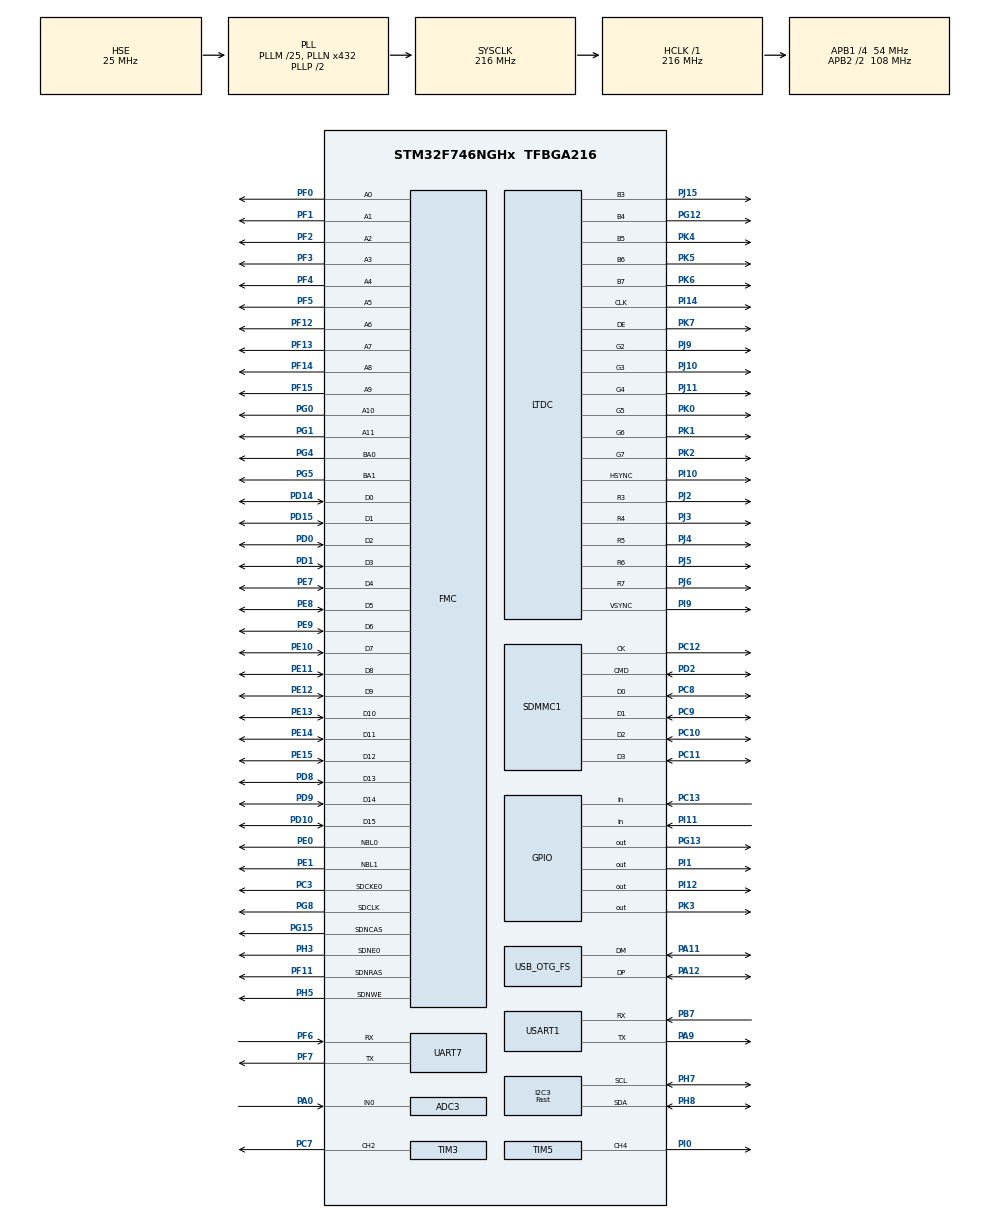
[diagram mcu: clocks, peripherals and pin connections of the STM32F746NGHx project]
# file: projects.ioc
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ADC3.Channel-0\#ChannelRegularConversion=ADC_CHANNEL_0
ADC3.ContinuousConvMode=DISABLE
ADC3.DMAContinuousRequests=ENABLE
ADC3.ExternalTrigConv=ADC_EXTERNALTRIGCONV_T2_CC2
ADC3.NbrOfConversion=1
ADC3.NbrOfConversionFlag=1
ADC3.Rank-0\#ChannelRegularConversion=1
ADC3.SamplingTime-0\#ChannelRegularConversion=ADC_SAMPLETIME_15CYCLES
ADC3.ScanConvMode=ADC_SCAN_DISABLE
CORTEX_M7.CPU_DCache=Disabled
CORTEX_M7.CPU_ICache=Enabled
CORTEX_M7.MPU_Control=__NULL
CORTEX_M7.PREFETCH_ENABLE=1
Dma.ADC3.0.Direction=DMA_PERIPH_TO_MEMORY
Dma.ADC3.0.FIFOMode=DMA_FIFOMODE_DISABLE
Dma.ADC3.0.Instance=DMA2_Stream1
Dma.ADC3.0.MemDataAlignment=DMA_MDATAALIGN_HALFWORD
Dma.ADC3.0.MemInc=DMA_MINC_ENABLE
Dma.ADC3.0.Mode=DMA_CIRCULAR
Dma.ADC3.0.PeriphDataAlignment=DMA_PDATAALIGN_HALFWORD
Dma.ADC3.0.PeriphInc=DMA_PINC_DISABLE
Dma.ADC3.0.Priority=DMA_PRIORITY_LOW
Dma.Request0=ADC3
Dma.Request1=SDMMC1_RX
Dma.Request2=SDMMC1_TX
Dma.Request3=TIM5_CH4/TRIG
Dma.SDMMC1_RX.1.Direction=DMA_PERIPH_TO_MEMORY
Dma.SDMMC1_RX.1.FIFOMode=DMA_FIFOMODE_ENABLE
Dma.SDMMC1_RX.1.FIFOThreshold=DMA_FIFO_THRESHOLD_FULL
Dma.SDMMC1_RX.1.Instance=DMA2_Stream3
Dma.SDMMC1_RX.1.MemBurst=DMA_MBURST_INC4
Dma.SDMMC1_RX.1.MemDataAlignment=DMA_MDATAALIGN_WORD
Dma.SDMMC1_RX.1.MemInc=DMA_MINC_ENABLE
Dma.SDMMC1_RX.1.Mode=DMA_PFCTRL
Dma.SDMMC1_RX.1.PeriphBurst=DMA_PBURST_INC4
Dma.SDMMC1_RX.1.PeriphDataAlignment=DMA_PDATAALIGN_WORD
Dma.SDMMC1_RX.1.PeriphInc=DMA_PINC_DISABLE
Dma.SDMMC1_RX.1.Priority=DMA_PRIORITY_LOW
Dma.SDMMC1_TX.2.Direction=DMA_MEMORY_TO_PERIPH
Dma.SDMMC1_TX.2.FIFOMode=DMA_FIFOMODE_ENABLE
Dma.SDMMC1_TX.2.FIFOThreshold=DMA_FIFO_THRESHOLD_FULL
Dma.SDMMC1_TX.2.Instance=DMA2_Stream6
Dma.SDMMC1_TX.2.MemBurst=DMA_MBURST_INC4
Dma.SDMMC1_TX.2.MemDataAlignment=DMA_MDATAALIGN_WORD
Dma.SDMMC1_TX.2.MemInc=DMA_MINC_ENABLE
Dma.SDMMC1_TX.2.Mode=DMA_PFCTRL
Dma.SDMMC1_TX.2.PeriphBurst=DMA_PBURST_INC4
Dma.SDMMC1_TX.2.PeriphDataAlignment=DMA_PDATAALIGN_WORD
Dma.SDMMC1_TX.2.PeriphInc=DMA_PINC_DISABLE
Dma.SDMMC1_TX.2.Priority=DMA_PRIORITY_LOW
Dma.TIM5_CH4/TRIG.3.Direction=DMA_MEMORY_TO_PERIPH
Dma.TIM5_CH4/TRIG.3.FIFOMode=DMA_FIFOMODE_DISABLE
Dma.TIM5_CH4/TRIG.3.Instance=DMA1_Stream1
Dma.TIM5_CH4/TRIG.3.MemDataAlignment=DMA_MDATAALIGN_WORD
Dma.TIM5_CH4/TRIG.3.MemInc=DMA_MINC_ENABLE
Dma.TIM5_CH4/TRIG.3.Mode=DMA_NORMAL
Dma.TIM5_CH4/TRIG.3.PeriphDataAlignment=DMA_PDATAALIGN_WORD
Dma.TIM5_CH4/TRIG.3.PeriphInc=DMA_PINC_DISABLE
Dma.TIM5_CH4/TRIG.3.Priority=DMA_PRIORITY_LOW
FATFS.BSP.number=1
FATFS._FS_LOCK=4
FATFS._USE_LFN=2
FATFS0.BSP.STBoard=false
FATFS0.BSP.api=Unknown
FATFS0.BSP.i2caddr=0
FATFS0.BSP.instance=PC13
FATFS0.BSP.ip=GPIO
FATFS0.BSP.mode=Input
FATFS0.BSP.name=Detect_SDIO
FATFS0.BSP.solution=PC13
FMC.CASLatency1=FMC_SDRAM_CAS_LATENCY_3
FMC.ExitSelfRefreshDelay1=7
FMC.LoadToActiveDelay1=2
FMC.RCDDelay1=2
FMC.RPDelay1=2
FMC.ReadBurst1=FMC_SDRAM_RBURST_ENABLE
FMC.RowCycleDelay1=7
FMC.SDClockPeriod1=FMC_SDRAM_CLOCK_PERIOD_2
FMC.SelfRefreshTime1=4
FMC.WriteRecoveryTime1=3
FREERTOS.Tasks01=defaultTask,0,128,StartDefaultTask,Default,NULL,Dynamic,NULL,NULL
FREERTOS.configTOTAL_HEAP_SIZE=30720
FREERTOS.configUSE_IDLE_HOOK=1
FREERTOS.configUSE_TICK_HOOK=1
FREERTOS.configUSE_TIMERS=1
GRAPHICS.BSP.number=1
GRAPHICS.Check_OTM8009A_PixelFormat-STemWin=1
GRAPHICS.DMA2D_Graphics-STemWin=0
GRAPHICS.EA_1_Apptype=Window
GRAPHICS.EA_1_custom_path=custom_off
GRAPHICS.EA_1_executable_name-STemWin=GUIBuilder.exe
GRAPHICS.GUI_NUM_LAYERS-STemWin=1
GRAPHICS.GUI_Num_KBYTES=40
GRAPHICS.LIN_Color_Conversion_Layer0=GUICC_M565
GRAPHICS.LIN_Frame_Buffer_Depth_Layer0-STemWin=16
GRAPHICS.Num_MultBuffers=1
GRAPHICS.Num_VScreens=1
GRAPHICS.OPTIM_OS_use-STemWin=2
GRAPHICS.USE_Embedded_Wizard-STemWin=0
GRAPHICS.USE_STTouchGFX-STemWin=0
GRAPHICS.UseGUIBuilder=Disabled
GRAPHICS.Use_SDRAM-STemWin=SDRAM1_BANK1
GRAPHICS0.BSP.STBoard=false
GRAPHICS0.BSP.api=Unknown
GRAPHICS0.BSP.i2caddr=0
GRAPHICS0.BSP.instance=PG13
GRAPHICS0.BSP.ip=GPIO
GRAPHICS0.BSP.mode=Output
GRAPHICS0.BSP.name=LCD Reset Pin XRES
GRAPHICS0.BSP.solution=PG13
I2C3.I2C_Speed_Mode=I2C_Fast
I2C3.Timing=0x6000030D
LTDC.ActiveH=272
LTDC.ActiveW=480
LTDC.Alpha_L0=255
LTDC.Blue_L0=0
LTDC.Blue_L1=22
LTDC.FBStartAdress_L0=0xC0000000
LTDC.FBStartAdress_L1=0x20050000
LTDC.Green_L0=0
LTDC.Green_L1=33
LTDC.HBP=43
LTDC.HFP=8
LTDC.HSync=1
LTDC.ImageHeight_L0=272
LTDC.ImageHeight_L1=272
LTDC.ImageWidth_L0=480
LTDC.ImageWidth_L1=480
LTDC.Layers=0
LTDC.PixelFormat_L0=LTDC_PIXEL_FORMAT_RGB565
LTDC.PixelFormat_L1=LTDC_PIXEL_FORMAT_RGB565
LTDC.Red_L0=0
LTDC.Red_L1=44
LTDC.VBP=12
LTDC.VFP=4
LTDC.VSync=10
LTDC.WindowX1_L0=480
LTDC.WindowX1_L1=480
LTDC.WindowY1_L0=272
LTDC.WindowY1_L1=272
Mcu.Family=STM32F7
Mcu.Name=STM32F746NGHx
Mcu.Package=TFBGA216
NVIC.ADC_IRQn=true\:5\:0\:false\:false\:true\:true\:true\:true
NVIC.DMA1_Stream1_IRQn=true\:5\:0\:true\:false\:true\:false\:false\:true
NVIC.DMA2_Stream1_IRQn=true\:5\:0\:true\:false\:true\:true\:false\:true
NVIC.DMA2_Stream3_IRQn=true\:5\:0\:false\:false\:true\:true\:false\:true
NVIC.DMA2_Stream6_IRQn=true\:5\:0\:true\:false\:true\:true\:false\:true
NVIC.OTG_FS_IRQn=true\:5\:0\:false\:false\:true\:true\:false\:true
NVIC.PriorityGroup=NVIC_PRIORITYGROUP_4
NVIC.SDMMC1_IRQn=true\:10\:0\:true\:false\:true\:true\:true\:true
NVIC.TIM1_UP_TIM10_IRQn=true\:0\:0\:false\:false\:true\:false\:false\:true
NVIC.TIM8_BRK_TIM12_IRQn=true\:1\:0\:true\:false\:true\:false\:true\:true
NVIC.TimeBase=TIM1_UP_TIM10_IRQn
NVIC.TimeBaseIP=TIM1
NVIC.USART1_IRQn=true\:5\:0\:false\:false\:true\:true\:true\:true
PA0/WKUP.Signal=ADCx_IN0
PA11.Mode=Device_Only
PA11.Signal=USB_OTG_FS_DM
PA12.Mode=Device_Only
PA12.Signal=USB_OTG_FS_DP
PA13.Mode=Trace_Asynchronous_SW
PA13.Signal=SYS_JTMS-SWDIO
PA14.Mode=Trace_Asynchronous_SW
PA14.Signal=SYS_JTCK-SWCLK
PA9.Mode=Asynchronous
PA9.Signal=USART1_TX
PB3.Mode=Trace_Asynchronous_SW
PB3.Signal=SYS_JTDO-SWO
PB7.Mode=Asynchronous
PB7.Signal=USART1_RX
PC10.Mode=SD_4_bits_Wide_bus
PC10.Signal=SDMMC1_D2
PC11.Mode=SD_4_bits_Wide_bus
PC11.Signal=SDMMC1_D3
PC12.Mode=SD_4_bits_Wide_bus
PC12.Signal=SDMMC1_CK
PC13.Signal=GPIO_Input
PC3.Mode=SdramChipSelect1_1
PC3.Signal=FMC_SDCKE0
PC7.Signal=S_TIM3_CH2
PC8.Mode=SD_4_bits_Wide_bus
PC8.Signal=SDMMC1_D0
PC9.Mode=SD_4_bits_Wide_bus
PC9.Signal=SDMMC1_D1
PD0.Signal=FMC_D2_DA2
PD1.Signal=FMC_D3_DA3
PD10.Signal=FMC_D15_DA15
PD14.Signal=FMC_D0_DA0
PD15.Signal=FMC_D1_DA1
PD2.Mode=SD_4_bits_Wide_bus
PD2.Signal=SDMMC1_CMD
PD8.Signal=FMC_D13_DA13
PD9.Signal=FMC_D14_DA14
PE0.Signal=FMC_NBL0
PE1.Signal=FMC_NBL1
PE10.Signal=FMC_D7_DA7
PE11.Signal=FMC_D8_DA8
PE12.Signal=FMC_D9_DA9
PE13.Signal=FMC_D10_DA10
PE14.Signal=FMC_D11_DA11
PE15.Signal=FMC_D12_DA12
PE7.Signal=FMC_D4_DA4
PE8.Signal=FMC_D5_DA5
PE9.Signal=FMC_D6_DA6
PF0.Signal=FMC_A0
PF1.Signal=FMC_A1
PF11.Signal=FMC_SDNRAS
PF12.Signal=FMC_A6
PF13.Signal=FMC_A7
PF14.Signal=FMC_A8
PF15.Signal=FMC_A9
PF2.Signal=FMC_A2
PF3.Signal=FMC_A3
PF4.Signal=FMC_A4
PF5.Signal=FMC_A5
PF6.Mode=Asynchronous
PF6.Signal=UART7_RX
PF7.Mode=Asynchronous
PF7.Signal=UART7_TX
PG0.Signal=FMC_A10
PG1.Signal=FMC_A11
PG12.GPIO_Speed=GPIO_SPEED_FREQ_HIGH
PG12.Mode=RGB565
PG12.Signal=LTDC_B4
PG13.Signal=GPIO_Output
PG15.Signal=FMC_SDNCAS
PG4.Signal=FMC_A14_BA0
PG5.Signal=FMC_A15_BA1
PG8.Signal=FMC_SDCLK
PH0/OSC_IN.Mode=HSE-External-Oscillator
PH0/OSC_IN.Signal=RCC_OSC_IN
PH1/OSC_OUT.Mode=HSE-External-Oscillator
PH1/OSC_OUT.Signal=RCC_OSC_OUT
PH3.Mode=SdramChipSelect1_1
PH3.Signal=FMC_SDNE0
PH5.Signal=FMC_SDNWE
PH7.Mode=I2C
PH7.Signal=I2C3_SCL
PH8.Mode=I2C
PH8.Signal=I2C3_SDA
PI0.GPIO_Speed=GPIO_SPEED_FREQ_HIGH
PI0.Signal=S_TIM5_CH4
PI1.Signal=GPIO_Output
PI10.GPIO_Speed=GPIO_SPEED_FREQ_HIGH
PI10.Mode=RGB565
PI10.Signal=LTDC_HSYNC
PI11.Signal=GPIO_Input
PI12.PinState=GPIO_PIN_SET
PI12.Signal=GPIO_Output
PI14.GPIO_Speed=GPIO_SPEED_FREQ_HIGH
PI14.Mode=RGB565
PI14.Signal=LTDC_CLK
PI9.GPIO_Speed=GPIO_SPEED_FREQ_HIGH
PI9.Mode=RGB565
PI9.Signal=LTDC_VSYNC
PJ10.GPIO_Speed=GPIO_SPEED_FREQ_HIGH
PJ10.Mode=RGB565
PJ10.Signal=LTDC_G3
PJ11.GPIO_Speed=GPIO_SPEED_FREQ_HIGH
PJ11.Mode=RGB565
PJ11.Signal=LTDC_G4
PJ15.GPIO_Speed=GPIO_SPEED_FREQ_HIGH
PJ15.Mode=RGB565
PJ15.Signal=LTDC_B3
PJ2.GPIO_Speed=GPIO_SPEED_FREQ_HIGH
PJ2.Mode=RGB565
PJ2.Signal=LTDC_R3
PJ3.GPIO_Speed=GPIO_SPEED_FREQ_HIGH
PJ3.Mode=RGB565
PJ3.Signal=LTDC_R4
PJ4.GPIO_Speed=GPIO_SPEED_FREQ_HIGH
PJ4.Mode=RGB565
PJ4.Signal=LTDC_R5
PJ5.GPIO_Speed=GPIO_SPEED_FREQ_HIGH
PJ5.Mode=RGB565
PJ5.Signal=LTDC_R6
PJ6.GPIO_Speed=GPIO_SPEED_FREQ_HIGH
PJ6.Mode=RGB565
PJ6.Signal=LTDC_R7
PJ9.GPIO_Speed=GPIO_SPEED_FREQ_HIGH
PJ9.Mode=RGB565
PJ9.Signal=LTDC_G2
PK0.GPIO_Speed=GPIO_SPEED_FREQ_HIGH
PK0.Mode=RGB565
PK0.Signal=LTDC_G5
PK1.GPIO_Speed=GPIO_SPEED_FREQ_HIGH
PK1.Mode=RGB565
PK1.Signal=LTDC_G6
PK2.GPIO_Speed=GPIO_SPEED_FREQ_HIGH
PK2.Mode=RGB565
PK2.Signal=LTDC_G7
PK3.PinState=GPIO_PIN_SET
PK3.Signal=GPIO_Output
PK4.GPIO_Speed=GPIO_SPEED_FREQ_HIGH
PK4.Mode=RGB565
PK4.Signal=LTDC_B5
PK5.GPIO_Speed=GPIO_SPEED_FREQ_HIGH
PK5.Mode=RGB565
PK5.Signal=LTDC_B6
PK6.GPIO_Speed=GPIO_SPEED_FREQ_HIGH
PK6.Mode=RGB565
PK6.Signal=LTDC_B7
PK7.GPIO_Speed=GPIO_SPEED_FREQ_HIGH
PK7.Mode=RGB565
PK7.Signal=LTDC_DE
ProjectManager.HeapSize=0x2000
ProjectManager.StackSize=0x2000
ProjectManager.TargetToolchain=EWARM V8
RCC.AHBFreq_Value=216000000
RCC.APB1CLKDivider=RCC_HCLK_DIV4
RCC.APB1Freq_Value=54000000
RCC.APB1TimFreq_Value=108000000
RCC.APB2CLKDivider=RCC_HCLK_DIV2
RCC.APB2Freq_Value=108000000
RCC.APB2TimFreq_Value=216000000
RCC.CortexFreq_Value=216000000
RCC.EnbaleCSS=true
RCC.HCLKFreq_Value=216000000
RCC.HSE_VALUE=25000000
RCC.HSI_VALUE=16000000
RCC.LSE_VALUE=32768
RCC.PLLM=25
RCC.PLLN=432
RCC.PLLQ=9
RCC.PLLSAIN=200
RCC.PLLSAIR=5
RCC.PLLSAIRDiv=RCC_PLLSAIDIVR_4
RCC.SDMMCClockSelection=RCC_SDMMC1CLKSOURCE_CLK48
RCC.SYSCLKFreq_VALUE=216000000
RCC.SYSCLKSource=RCC_SYSCLKSOURCE_PLLCLK
RCC.USBFreq_Value=48000000
RCC.VCOOutputFreq_Value=432000000
SDMMC1.ClockDiv=0
SH.ADCx_IN0.0=ADC3_IN0,IN0
SH.FMC_A0.0=FMC_A0,12b-sda1
SH.FMC_A1.0=FMC_A1,12b-sda1
SH.FMC_A10.0=FMC_A10,12b-sda1
SH.FMC_A11.0=FMC_A11,12b-sda1
SH.FMC_A14_BA0.0=FMC_BA0,FourSdramBanks1
SH.FMC_A15_BA1.0=FMC_BA1,FourSdramBanks1
SH.FMC_A2.0=FMC_A2,12b-sda1
SH.FMC_A3.0=FMC_A3,12b-sda1
SH.FMC_A4.0=FMC_A4,12b-sda1
SH.FMC_A5.0=FMC_A5,12b-sda1
SH.FMC_A6.0=FMC_A6,12b-sda1
SH.FMC_A7.0=FMC_A7,12b-sda1
SH.FMC_A8.0=FMC_A8,12b-sda1
SH.FMC_A9.0=FMC_A9,12b-sda1
SH.FMC_D0_DA0.0=FMC_D0,sd-16b-d1
SH.FMC_D10_DA10.0=FMC_D10,sd-16b-d1
SH.FMC_D11_DA11.0=FMC_D11,sd-16b-d1
SH.FMC_D12_DA12.0=FMC_D12,sd-16b-d1
SH.FMC_D13_DA13.0=FMC_D13,sd-16b-d1
SH.FMC_D14_DA14.0=FMC_D14,sd-16b-d1
SH.FMC_D15_DA15.0=FMC_D15,sd-16b-d1
SH.FMC_D1_DA1.0=FMC_D1,sd-16b-d1
SH.FMC_D2_DA2.0=FMC_D2,sd-16b-d1
SH.FMC_D3_DA3.0=FMC_D3,sd-16b-d1
SH.FMC_D4_DA4.0=FMC_D4,sd-16b-d1
SH.FMC_D5_DA5.0=FMC_D5,sd-16b-d1
SH.FMC_D6_DA6.0=FMC_D6,sd-16b-d1
SH.FMC_D7_DA7.0=FMC_D7,sd-16b-d1
SH.FMC_D8_DA8.0=FMC_D8,sd-16b-d1
SH.FMC_D9_DA9.0=FMC_D9,sd-16b-d1
SH.FMC_NBL0.0=FMC_NBL0,Sd2ByteEnable1
SH.FMC_NBL1.0=FMC_NBL1,Sd2ByteEnable1
SH.FMC_SDCLK.0=FMC_SDCLK,12b-sda1
SH.FMC_SDNCAS.0=FMC_SDNCAS,12b-sda1
SH.FMC_SDNRAS.0=FMC_SDNRAS,12b-sda1
SH.FMC_SDNWE.0=FMC_SDNWE,12b-sda1
SH.S_TIM3_CH2.0=TIM3_CH2,PWM Generation2 CH2
SH.S_TIM5_CH4.0=TIM5_CH4,PWM Generation4 CH4
TIM12.Period=10000-1
TIM12.Prescaler=10800-1
TIM2.Channel-PWM\ Generation2\ No\ Output=TIM_CHANNEL_2
TIM2.Period=27-1
TIM2.Prescaler=100-1
TIM2.Pulse-PWM\ Generation2\ No\ Output=10
TIM3.Channel-PWM\ Generation2\ CH2=TIM_CHANNEL_2
TIM3.Period=10000-1
TIM3.Prescaler=10800-1
TIM3.Pulse-PWM\ Generation2\ CH2=3000
TIM5.AutoReloadPreload=TIM_AUTORELOAD_PRELOAD_DISABLE
TIM5.Channel-PWM\ Generation4\ CH4=TIM_CHANNEL_4
TIM5.Period=100
TIM5.Prescaler=108-1
TIM5.Pulse-PWM\ Generation4\ CH4=0
USART1.VirtualMode-Asynchronous=VM_ASYNC
USB_DEVICE.CLASS_NAME_FS=MSC
USB_DEVICE.VirtualMode-MSC_FS=Msc
USB_DEVICE.VirtualModeFS=Msc_FS
USB_OTG_FS.VirtualMode=Device_Only
VP_CRC_VS_CRC.Mode=CRC_Activate
VP_FATFS_VS_SDIO.Mode=SDIO
VP_FREERTOS_VS_CMSIS_V1.Mode=CMSIS_V1
VP_GRAPHICS_VS-DisplayInterface-LTDC.Mode=Display Parallel Interface using LTDC
VP_GRAPHICS_VS-STemWin.Mode=STemWin
VP_SYS_VS_tim1.Mode=TIM1
VP_TIM12_VS_ClockSourceINT.Mode=Internal
VP_TIM2_VS_ClockSourceINT.Mode=Internal
VP_TIM2_VS_no_output2.Mode=PWM Generation2 No Output
VP_TIM3_VS_ClockSourceINT.Mode=Internal
VP_TIM5_VS_ClockSourceINT.Mode=Internal
VP_USB_DEVICE_VS_USB_DEVICE_MSC_FS.Mode=MSC_FS
board=custom

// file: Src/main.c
/* USER CODE BEGIN Header */
/**
  ******************************************************************************
  * @file           : main.c
  * @brief          : Main program body
  ******************************************************************************
  * @attention
  *
  * <h2><center>&copy; Copyright (c) 2021 STMicroelectronics.
  * All rights reserved.</center></h2>
  *
  * This software component is licensed by ST under BSD 3-Clause license,
  * the "License"; You may not use this file except in compliance with the
  * License. You may obtain a copy of the License at:
  *                        opensource.org/licenses/BSD-3-Clause
  *
  ******************************************************************************
  */
/* USER CODE END Header */

#include "main.h"
#include "cmsis_os.h"
#include "fatfs.h"
#include "usb_device.h"

/* USER CODE BEGIN Includes */
#include "os_threads.h"
#include "os_time.h"
/* USER CODE END Includes */

/* USER CODE BEGIN PM */
#define TOUCH_POS(a, b)       (((a << 8) | b) & 0x0fff)
/* USER CODE END PM */

ADC_HandleTypeDef hadc3;
DMA_HandleTypeDef hdma_adc3;

CRC_HandleTypeDef hcrc;

I2C_HandleTypeDef hi2c3;

SD_HandleTypeDef hsd1;
DMA_HandleTypeDef hdma_sdmmc1_rx;
DMA_HandleTypeDef hdma_sdmmc1_tx;

TIM_HandleTypeDef htim2;
TIM_HandleTypeDef htim3;
TIM_HandleTypeDef htim5;
TIM_HandleTypeDef htim12;
DMA_HandleTypeDef hdma_tim5_ch4_trig;

UART_HandleTypeDef huart7;
UART_HandleTypeDef huart1;

osThreadId defaultTaskHandle;
/* USER CODE BEGIN PV */
uint16_t System_Restart_Request = 0;
/* USER CODE END PV */

void SystemClock_Config(void);
static void MX_GPIO_Init(void);
static void MX_DMA_Init(void);
static void MX_I2C3_Init(void);
static void MX_CRC_Init(void);
extern void GRAPHICS_HW_Init(void);
extern void GRAPHICS_Init(void);
extern void GRAPHICS_MainTask(void);
static void MX_TIM2_Init(void);
static void MX_TIM3_Init(void);
static void MX_ADC3_Init(void);
static void MX_SDMMC1_SD_Init(void);
static void MX_UART7_Init(void);
static void MX_TIM5_Init(void);
static void MX_USART1_UART_Init(void);
static void MX_TIM12_Init(void);
void StartDefaultTask(void const * argument);

/* USER CODE BEGIN PFP */
static void MPU_Config(void);
void vLCDTimerCraete();
/* USER CODE END PFP */

/* USER CODE BEGIN 0 */
// printf �?定�?�到串�?�
int fputc(int ch, FILE *f)
{
  HAL_UART_Transmit(&huart1, (uint8_t *)&ch, 1, 0xffff);
  return ch;
}

uint16_t Audio_DMA_Ready;                     // DMA 就绪标志
/**
  * @brief  ADC3 IN0 �??????????? DMA 完�?中断
  * @param  ADC_HandleTypeDef *hadc
  * @retval None
  */
void HAL_ADC_ConvCpltCallback(ADC_HandleTypeDef *hadc)
{
  Audio_DMA_Ready = 1;
}
/* USER CODE END 0 */

int main(void)
{
  /* USER CODE BEGIN 1 */
  /* Configure the MPU attributes */
  MPU_Config();

  /* Invalidate I-Cache : ICIALLU register */
  /* Enable branch prediction */
  SCB->CCR |= (1 << 18);
   __DSB();
  /* USER CODE END 1 */

  /* Enable I-Cache---------------------------------------------------------*/
  SCB_EnableICache();

  /* MCU Configuration--------------------------------------------------------*/

  /* Reset of all peripherals, Initializes the Flash interface and the Systick. */
  HAL_Init();

  /* Configure the system clock */
  SystemClock_Config();

  /* Initialize all configured peripherals */
  MX_GPIO_Init();
  MX_DMA_Init();
  MX_I2C3_Init();
  MX_CRC_Init();
  MX_TIM2_Init();
  MX_TIM3_Init();
  MX_ADC3_Init();
  MX_SDMMC1_SD_Init();
  MX_UART7_Init();
  MX_TIM5_Init();
  MX_USART1_UART_Init();
  MX_TIM12_Init();
  /* USER CODE BEGIN 2 */
  HAL_TIM_Base_Start_IT(&htim12);     // 开�?� TIM 12 的中断，用于更新系统时间
  BSP_SDRAM_Init();                   // �?始化 SDRAM
  /* USER CODE END 2 */

/* Initialise the graphical hardware */
  GRAPHICS_HW_Init();

  /* Initialise the graphical stack engine */
  GRAPHICS_Init();

  /* USER CODE BEGIN RTOS_TIMERS */
  /* start timers, add new ones, ... */
  vLCDTimerCraete();                    // �?�动触摸�?检测定时器 (RTOS 软定时)
  /* USER CODE END RTOS_TIMERS */

  /* USER CODE BEGIN RTOS_QUEUES */
  /* add queues, ... */
  #ifdef CMSIS_V2
  /* USER CODE END RTOS_QUEUES */

  /* Create the thread(s) */
  /* definition and creation of defaultTask */
  osThreadDef(defaultTask, StartDefaultTask, osPriorityNormal, 0, 128);
  defaultTaskHandle = osThreadCreate(osThread(defaultTask), NULL);

  /* USER CODE BEGIN RTOS_THREADS */
  osThreadTerminate(defaultTaskHandle);
  #endif
  /* add threads, ... */
  vStorageTaskCreate();                 // �?�动存储线程，对 SD �?�进行�?始化
  vGUITaskCreate();                     // �?�动 GUI task
  #ifdef CMSIS_V1
  vTaskStartScheduler();                // 开�?�任务调度器 (RTOS)
  #endif
  //
  /* USER CODE END RTOS_THREADS */

  /* Start scheduler */
  osKernelStart();

  /* We should never get here as control is now taken by the scheduler */

  /* Infinite loop */
  /* USER CODE BEGIN WHILE */
  // 正常情况下永远都�?会�?行到这里
  while (1)
  {
    osDelay(100);
    /* USER CODE END WHILE */

  }
}

void SystemClock_Config(void)
{
  RCC_OscInitTypeDef RCC_OscInitStruct = {0};
  RCC_ClkInitTypeDef RCC_ClkInitStruct = {0};
  RCC_PeriphCLKInitTypeDef PeriphClkInitStruct = {0};

  /** Configure the main internal regulator output voltage
  */
  __HAL_RCC_PWR_CLK_ENABLE();
  __HAL_PWR_VOLTAGESCALING_CONFIG(PWR_REGULATOR_VOLTAGE_SCALE1);
  /** Initializes the CPU, AHB and APB busses clocks
  */
  RCC_OscInitStruct.OscillatorType = RCC_OSCILLATORTYPE_HSE;
  RCC_OscInitStruct.HSEState = RCC_HSE_ON;
  RCC_OscInitStruct.PLL.PLLState = RCC_PLL_ON;
  RCC_OscInitStruct.PLL.PLLSource = RCC_PLLSOURCE_HSE;
  RCC_OscInitStruct.PLL.PLLM = 25;
  RCC_OscInitStruct.PLL.PLLN = 432;
  RCC_OscInitStruct.PLL.PLLP = RCC_PLLP_DIV2;
  RCC_OscInitStruct.PLL.PLLQ = 9;
  if (HAL_RCC_OscConfig(&RCC_OscInitStruct) != HAL_OK)
  {
    Error_Handler();
  }
  /** Activate the Over-Drive mode
  */
  if (HAL_PWREx_EnableOverDrive() != HAL_OK)
  {
    Error_Handler();
  }
  /** Initializes the CPU, AHB and APB busses clocks
  */
  RCC_ClkInitStruct.ClockType = RCC_CLOCKTYPE_HCLK|RCC_CLOCKTYPE_SYSCLK
                              |RCC_CLOCKTYPE_PCLK1|RCC_CLOCKTYPE_PCLK2;
  RCC_ClkInitStruct.SYSCLKSource = RCC_SYSCLKSOURCE_PLLCLK;
  RCC_ClkInitStruct.AHBCLKDivider = RCC_SYSCLK_DIV1;
  RCC_ClkInitStruct.APB1CLKDivider = RCC_HCLK_DIV4;
  RCC_ClkInitStruct.APB2CLKDivider = RCC_HCLK_DIV2;

  if (HAL_RCC_ClockConfig(&RCC_ClkInitStruct, FLASH_LATENCY_7) != HAL_OK)
  {
    Error_Handler();
  }
  PeriphClkInitStruct.PeriphClockSelection = RCC_PERIPHCLK_LTDC|RCC_PERIPHCLK_USART1
                              |RCC_PERIPHCLK_UART7|RCC_PERIPHCLK_I2C3
                              |RCC_PERIPHCLK_SDMMC1|RCC_PERIPHCLK_CLK48;
  PeriphClkInitStruct.PLLSAI.PLLSAIN = 200;
  PeriphClkInitStruct.PLLSAI.PLLSAIR = 5;
  PeriphClkInitStruct.PLLSAI.PLLSAIQ = 2;
  PeriphClkInitStruct.PLLSAI.PLLSAIP = RCC_PLLSAIP_DIV2;
  PeriphClkInitStruct.PLLSAIDivQ = 1;
  PeriphClkInitStruct.PLLSAIDivR = RCC_PLLSAIDIVR_4;
  PeriphClkInitStruct.Usart1ClockSelection = RCC_USART1CLKSOURCE_PCLK2;
  PeriphClkInitStruct.Uart7ClockSelection = RCC_UART7CLKSOURCE_PCLK1;
  PeriphClkInitStruct.I2c3ClockSelection = RCC_I2C3CLKSOURCE_PCLK1;
  PeriphClkInitStruct.Clk48ClockSelection = RCC_CLK48SOURCE_PLL;
  PeriphClkInitStruct.Sdmmc1ClockSelection = RCC_SDMMC1CLKSOURCE_CLK48;
  if (HAL_RCCEx_PeriphCLKConfig(&PeriphClkInitStruct) != HAL_OK)
  {
    Error_Handler();
  }
  /** Enables the Clock Security System
  */
  HAL_RCC_EnableCSS();
}

static void MX_ADC3_Init(void)
{

  ADC_ChannelConfTypeDef sConfig = {0};

  /** Configure the global features of the ADC (Clock, Resolution, Data Alignment and number of conversion)
  */
  hadc3.Instance = ADC3;
  hadc3.Init.ClockPrescaler = ADC_CLOCK_SYNC_PCLK_DIV4;
  hadc3.Init.Resolution = ADC_RESOLUTION_12B;
  hadc3.Init.ScanConvMode = ADC_SCAN_DISABLE;
  hadc3.Init.ContinuousConvMode = DISABLE;
  hadc3.Init.DiscontinuousConvMode = DISABLE;
  hadc3.Init.ExternalTrigConvEdge = ADC_EXTERNALTRIGCONVEDGE_RISING;
  hadc3.Init.ExternalTrigConv = ADC_EXTERNALTRIGCONV_T2_CC2;
  hadc3.Init.DataAlign = ADC_DATAALIGN_RIGHT;
  hadc3.Init.NbrOfConversion = 1;
  hadc3.Init.DMAContinuousRequests = ENABLE;
  hadc3.Init.EOCSelection = ADC_EOC_SINGLE_CONV;
  if (HAL_ADC_Init(&hadc3) != HAL_OK)
  {
    Error_Handler();
  }
  /** Configure for the selected ADC regular channel its corresponding rank in the sequencer and its sample time.
  */
  sConfig.Channel = ADC_CHANNEL_0;
  sConfig.Rank = ADC_REGULAR_RANK_1;
  sConfig.SamplingTime = ADC_SAMPLETIME_15CYCLES;
  if (HAL_ADC_ConfigChannel(&hadc3, &sConfig) != HAL_OK)
  {
    Error_Handler();
  }

}

static void MX_CRC_Init(void)
{

  hcrc.Instance = CRC;
  hcrc.Init.DefaultPolynomialUse = DEFAULT_POLYNOMIAL_ENABLE;
  hcrc.Init.DefaultInitValueUse = DEFAULT_INIT_VALUE_ENABLE;
  hcrc.Init.InputDataInversionMode = CRC_INPUTDATA_INVERSION_NONE;
  hcrc.Init.OutputDataInversionMode = CRC_OUTPUTDATA_INVERSION_DISABLE;
  hcrc.InputDataFormat = CRC_INPUTDATA_FORMAT_BYTES;
  if (HAL_CRC_Init(&hcrc) != HAL_OK)
  {
    Error_Handler();
  }

}

static void MX_I2C3_Init(void)
{

  hi2c3.Instance = I2C3;
  hi2c3.Init.Timing = 0x6000030D;
  hi2c3.Init.OwnAddress1 = 0;
  hi2c3.Init.AddressingMode = I2C_ADDRESSINGMODE_7BIT;
  hi2c3.Init.DualAddressMode = I2C_DUALADDRESS_DISABLE;
  hi2c3.Init.OwnAddress2 = 0;
  hi2c3.Init.OwnAddress2Masks = I2C_OA2_NOMASK;
  hi2c3.Init.GeneralCallMode = I2C_GENERALCALL_DISABLE;
  hi2c3.Init.NoStretchMode = I2C_NOSTRETCH_DISABLE;
  if (HAL_I2C_Init(&hi2c3) != HAL_OK)
  {
    Error_Handler();
  }
  /** Configure Analogue filter
  */
  if (HAL_I2CEx_ConfigAnalogFilter(&hi2c3, I2C_ANALOGFILTER_ENABLE) != HAL_OK)
  {
    Error_Handler();
  }
  /** Configure Digital filter
  */
  if (HAL_I2CEx_ConfigDigitalFilter(&hi2c3, 0) != HAL_OK)
  {
    Error_Handler();
  }

}

static void MX_SDMMC1_SD_Init(void)
{

  hsd1.Instance = SDMMC1;
  hsd1.Init.ClockEdge = SDMMC_CLOCK_EDGE_RISING;
  hsd1.Init.ClockBypass = SDMMC_CLOCK_BYPASS_DISABLE;
  hsd1.Init.ClockPowerSave = SDMMC_CLOCK_POWER_SAVE_DISABLE;
  hsd1.Init.BusWide = SDMMC_BUS_WIDE_1B;
  hsd1.Init.HardwareFlowControl = SDMMC_HARDWARE_FLOW_CONTROL_DISABLE;
  hsd1.Init.ClockDiv = 0;

}

static void MX_TIM2_Init(void)
{

  TIM_ClockConfigTypeDef sClockSourceConfig = {0};
  TIM_MasterConfigTypeDef sMasterConfig = {0};
  TIM_OC_InitTypeDef sConfigOC = {0};

  htim2.Instance = TIM2;
  htim2.Init.Prescaler = 100-1;
  htim2.Init.CounterMode = TIM_COUNTERMODE_UP;
  htim2.Init.Period = 27-1;
  htim2.Init.ClockDivision = TIM_CLOCKDIVISION_DIV1;
  htim2.Init.AutoReloadPreload = TIM_AUTORELOAD_PRELOAD_DISABLE;
  if (HAL_TIM_Base_Init(&htim2) != HAL_OK)
  {
    Error_Handler();
  }
  sClockSourceConfig.ClockSource = TIM_CLOCKSOURCE_INTERNAL;
  if (HAL_TIM_ConfigClockSource(&htim2, &sClockSourceConfig) != HAL_OK)
  {
    Error_Handler();
  }
  if (HAL_TIM_PWM_Init(&htim2) != HAL_OK)
  {
    Error_Handler();
  }
  sMasterConfig.MasterOutputTrigger = TIM_TRGO_RESET;
  sMasterConfig.MasterSlaveMode = TIM_MASTERSLAVEMODE_DISABLE;
  if (HAL_TIMEx_MasterConfigSynchronization(&htim2, &sMasterConfig) != HAL_OK)
  {
    Error_Handler();
  }
  sConfigOC.OCMode = TIM_OCMODE_PWM1;
  sConfigOC.Pulse = 10;
  sConfigOC.OCPolarity = TIM_OCPOLARITY_HIGH;
  sConfigOC.OCFastMode = TIM_OCFAST_DISABLE;
  if (HAL_TIM_PWM_ConfigChannel(&htim2, &sConfigOC, TIM_CHANNEL_2) != HAL_OK)
  {
    Error_Handler();
  }

}

static void MX_TIM3_Init(void)
{

  TIM_ClockConfigTypeDef sClockSourceConfig = {0};
  TIM_MasterConfigTypeDef sMasterConfig = {0};
  TIM_OC_InitTypeDef sConfigOC = {0};

  htim3.Instance = TIM3;
  htim3.Init.Prescaler = 10800-1;
  htim3.Init.CounterMode = TIM_COUNTERMODE_UP;
  htim3.Init.Period = 10000-1;
  htim3.Init.ClockDivision = TIM_CLOCKDIVISION_DIV1;
  htim3.Init.AutoReloadPreload = TIM_AUTORELOAD_PRELOAD_DISABLE;
  if (HAL_TIM_Base_Init(&htim3) != HAL_OK)
  {
    Error_Handler();
  }
  sClockSourceConfig.ClockSource = TIM_CLOCKSOURCE_INTERNAL;
  if (HAL_TIM_ConfigClockSource(&htim3, &sClockSourceConfig) != HAL_OK)
  {
    Error_Handler();
  }
  if (HAL_TIM_PWM_Init(&htim3) != HAL_OK)
  {
    Error_Handler();
  }
  sMasterConfig.MasterOutputTrigger = TIM_TRGO_RESET;
  sMasterConfig.MasterSlaveMode = TIM_MASTERSLAVEMODE_DISABLE;
  if (HAL_TIMEx_MasterConfigSynchronization(&htim3, &sMasterConfig) != HAL_OK)
  {
    Error_Handler();
  }
  sConfigOC.OCMode = TIM_OCMODE_PWM1;
  sConfigOC.Pulse = 3000;
  sConfigOC.OCPolarity = TIM_OCPOLARITY_HIGH;
  sConfigOC.OCFastMode = TIM_OCFAST_DISABLE;
  if (HAL_TIM_PWM_ConfigChannel(&htim3, &sConfigOC, TIM_CHANNEL_2) != HAL_OK)
  {
    Error_Handler();
  }
  HAL_TIM_MspPostInit(&htim3);

}

static void MX_TIM5_Init(void)
{

  TIM_ClockConfigTypeDef sClockSourceConfig = {0};
  TIM_MasterConfigTypeDef sMasterConfig = {0};
  TIM_OC_InitTypeDef sConfigOC = {0};

  htim5.Instance = TIM5;
  htim5.Init.Prescaler = 108-1;
  htim5.Init.CounterMode = TIM_COUNTERMODE_UP;
  htim5.Init.Period = 100;
  htim5.Init.ClockDivision = TIM_CLOCKDIVISION_DIV1;
  htim5.Init.AutoReloadPreload = TIM_AUTORELOAD_PRELOAD_DISABLE;
  if (HAL_TIM_Base_Init(&htim5) != HAL_OK)
  {
    Error_Handler();
  }
  sClockSourceConfig.ClockSource = TIM_CLOCKSOURCE_INTERNAL;
  if (HAL_TIM_ConfigClockSource(&htim5, &sClockSourceConfig) != HAL_OK)
  {
    Error_Handler();
  }
  if (HAL_TIM_PWM_Init(&htim5) != HAL_OK)
  {
    Error_Handler();
  }
  sMasterConfig.MasterOutputTrigger = TIM_TRGO_RESET;
  sMasterConfig.MasterSlaveMode = TIM_MASTERSLAVEMODE_DISABLE;
  if (HAL_TIMEx_MasterConfigSynchronization(&htim5, &sMasterConfig) != HAL_OK)
  {
    Error_Handler();
  }
  sConfigOC.OCMode = TIM_OCMODE_PWM1;
  sConfigOC.Pulse = 0;
  sConfigOC.OCPolarity = TIM_OCPOLARITY_HIGH;
  sConfigOC.OCFastMode = TIM_OCFAST_DISABLE;
  if (HAL_TIM_PWM_ConfigChannel(&htim5, &sConfigOC, TIM_CHANNEL_4) != HAL_OK)
  {
    Error_Handler();
  }
  HAL_TIM_MspPostInit(&htim5);

}

static void MX_TIM12_Init(void)
{

  TIM_ClockConfigTypeDef sClockSourceConfig = {0};

  htim12.Instance = TIM12;
  htim12.Init.Prescaler = 10800-1;
  htim12.Init.CounterMode = TIM_COUNTERMODE_UP;
  htim12.Init.Period = 10000-1;
  htim12.Init.ClockDivision = TIM_CLOCKDIVISION_DIV1;
  htim12.Init.AutoReloadPreload = TIM_AUTORELOAD_PRELOAD_DISABLE;
  if (HAL_TIM_Base_Init(&htim12) != HAL_OK)
  {
    Error_Handler();
  }
  sClockSourceConfig.ClockSource = TIM_CLOCKSOURCE_INTERNAL;
  if (HAL_TIM_ConfigClockSource(&htim12, &sClockSourceConfig) != HAL_OK)
  {
    Error_Handler();
  }

}

static void MX_UART7_Init(void)
{

  huart7.Instance = UART7;
  huart7.Init.BaudRate = 115200;
  huart7.Init.WordLength = UART_WORDLENGTH_8B;
  huart7.Init.StopBits = UART_STOPBITS_1;
  huart7.Init.Parity = UART_PARITY_NONE;
  huart7.Init.Mode = UART_MODE_TX_RX;
  huart7.Init.HwFlowCtl = UART_HWCONTROL_NONE;
  huart7.Init.OverSampling = UART_OVERSAMPLING_16;
  huart7.Init.OneBitSampling = UART_ONE_BIT_SAMPLE_DISABLE;
  huart7.AdvancedInit.AdvFeatureInit = UART_ADVFEATURE_NO_INIT;
  if (HAL_UART_Init(&huart7) != HAL_OK)
  {
    Error_Handler();
  }

}

static void MX_USART1_UART_Init(void)
{

  huart1.Instance = USART1;
  huart1.Init.BaudRate = 115200;
  huart1.Init.WordLength = UART_WORDLENGTH_8B;
  huart1.Init.StopBits = UART_STOPBITS_1;
  huart1.Init.Parity = UART_PARITY_NONE;
  huart1.Init.Mode = UART_MODE_TX_RX;
  huart1.Init.HwFlowCtl = UART_HWCONTROL_NONE;
  huart1.Init.OverSampling = UART_OVERSAMPLING_16;
  huart1.Init.OneBitSampling = UART_ONE_BIT_SAMPLE_DISABLE;
  huart1.AdvancedInit.AdvFeatureInit = UART_ADVFEATURE_NO_INIT;
  if (HAL_UART_Init(&huart1) != HAL_OK)
  {
    Error_Handler();
  }

}

static void MX_DMA_Init(void)
{

  /* DMA controller clock enable */
  __HAL_RCC_DMA2_CLK_ENABLE();
  __HAL_RCC_DMA1_CLK_ENABLE();

  /* DMA interrupt init */
  /* DMA1_Stream1_IRQn interrupt configuration */
  HAL_NVIC_SetPriority(DMA1_Stream1_IRQn, 5, 0);
  HAL_NVIC_EnableIRQ(DMA1_Stream1_IRQn);
  /* DMA2_Stream1_IRQn interrupt configuration */
  HAL_NVIC_SetPriority(DMA2_Stream1_IRQn, 5, 0);
  HAL_NVIC_EnableIRQ(DMA2_Stream1_IRQn);
  /* DMA2_Stream3_IRQn interrupt configuration */
  HAL_NVIC_SetPriority(DMA2_Stream3_IRQn, 5, 0);
  HAL_NVIC_EnableIRQ(DMA2_Stream3_IRQn);
  /* DMA2_Stream6_IRQn interrupt configuration */
  HAL_NVIC_SetPriority(DMA2_Stream6_IRQn, 5, 0);
  HAL_NVIC_EnableIRQ(DMA2_Stream6_IRQn);

}

static void MX_GPIO_Init(void)
{
  GPIO_InitTypeDef GPIO_InitStruct = {0};

  /* GPIO Ports Clock Enable */
  __HAL_RCC_GPIOE_CLK_ENABLE();
  __HAL_RCC_GPIOB_CLK_ENABLE();
  __HAL_RCC_GPIOC_CLK_ENABLE();
  __HAL_RCC_GPIOA_CLK_ENABLE();
  __HAL_RCC_GPIOG_CLK_ENABLE();
  __HAL_RCC_GPIOD_CLK_ENABLE();
  __HAL_RCC_GPIOK_CLK_ENABLE();
  __HAL_RCC_GPIOF_CLK_ENABLE();
  __HAL_RCC_GPIOI_CLK_ENABLE();
  __HAL_RCC_GPIOJ_CLK_ENABLE();
  __HAL_RCC_GPIOH_CLK_ENABLE();

  /*Configure GPIO pin Output Level */
  HAL_GPIO_WritePin(GPIOG, GPIO_PIN_13, GPIO_PIN_RESET);

  /*Configure GPIO pin Output Level */
  HAL_GPIO_WritePin(GPIOK, GPIO_PIN_3, GPIO_PIN_SET);

  /*Configure GPIO pin Output Level */
  HAL_GPIO_WritePin(GPIOI, GPIO_PIN_1, GPIO_PIN_RESET);

  /*Configure GPIO pin Output Level */
  HAL_GPIO_WritePin(GPIOI, GPIO_PIN_12, GPIO_PIN_SET);

  /*Configure GPIO pin : PG13 */
  GPIO_InitStruct.Pin = GPIO_PIN_13;
  GPIO_InitStruct.Mode = GPIO_MODE_OUTPUT_PP;
  GPIO_InitStruct.Pull = GPIO_NOPULL;
  GPIO_InitStruct.Speed = GPIO_SPEED_FREQ_LOW;
  HAL_GPIO_Init(GPIOG, &GPIO_InitStruct);

  /*Configure GPIO pin : PC13 */
  GPIO_InitStruct.Pin = GPIO_PIN_13;
  GPIO_InitStruct.Mode = GPIO_MODE_INPUT;
  GPIO_InitStruct.Pull = GPIO_NOPULL;
  HAL_GPIO_Init(GPIOC, &GPIO_InitStruct);

  /*Configure GPIO pin : PK3 */
  GPIO_InitStruct.Pin = GPIO_PIN_3;
  GPIO_InitStruct.Mode = GPIO_MODE_OUTPUT_PP;
  GPIO_InitStruct.Pull = GPIO_NOPULL;
  GPIO_InitStruct.Speed = GPIO_SPEED_FREQ_LOW;
  HAL_GPIO_Init(GPIOK, &GPIO_InitStruct);

  /*Configure GPIO pins : PI1 PI12 */
  GPIO_InitStruct.Pin = GPIO_PIN_1|GPIO_PIN_12;
  GPIO_InitStruct.Mode = GPIO_MODE_OUTPUT_PP;
  GPIO_InitStruct.Pull = GPIO_NOPULL;
  GPIO_InitStruct.Speed = GPIO_SPEED_FREQ_LOW;
  HAL_GPIO_Init(GPIOI, &GPIO_InitStruct);

  /*Configure GPIO pin : PI11 */
  GPIO_InitStruct.Pin = GPIO_PIN_11;
  GPIO_InitStruct.Mode = GPIO_MODE_INPUT;
  GPIO_InitStruct.Pull = GPIO_NOPULL;
  HAL_GPIO_Init(GPIOI, &GPIO_InitStruct);

}

/* USER CODE BEGIN 4 */
#ifdef CMSIS_V1
/**
  * @brief  Timer callback for `TouchCheck` (40 ms)
  * @param  n: Timer index
  * @retval None
  */
static void TouchCheckTimerCallback(const void *n)
{
  uint8_t buf[6];
	HAL_I2C_Mem_Read(&hi2c3, 0x70, 0x02, 1, buf, 1, 1000);
	if (buf[0] > 0 && buf[0] < 6)
	{
		HAL_I2C_Mem_Read(&hi2c3, 0x70, 0x03, 1, buf, 4, 1000);
		GUI_TOUCH_StoreState(TOUCH_POS(buf[2], buf[3]), TOUCH_POS(buf[0], buf[1]));
	}
	else
		GUI_TOUCH_StoreState(-1, -1);
}
#endif

#ifdef CMSIS_V2
/**
  * @brief  Timer callback for `TouchCheck` (40 ms)
  * @param  n: Timer index
  * @retval None
  */
static void TouchCheckTimerCallback(void *n)
{
  uint8_t buf[6];
	HAL_I2C_Mem_Read(&hi2c3, 0x70, 0x02, 1, buf, 1, 1000);
	if (buf[0] > 0 && buf[0] < 6)
	{
		HAL_I2C_Mem_Read(&hi2c3, 0x70, 0x03, 1, buf, 4, 1000);
		GUI_TOUCH_StoreState(TOUCH_POS(buf[2], buf[3]), TOUCH_POS(buf[0], buf[1]));
	}
	else
		GUI_TOUCH_StoreState(-1, -1);
}
#endif

void vLCDTimerCraete()
{
#ifdef CMSIS_V1
  osTimerId timer_lcd;
  osTimerDef(timer_lcd, TouchCheckTimerCallback);
  timer_lcd = osTimerCreate(osTimer(timer_lcd), osTimerPeriodic, NULL);
  osTimerStart(timer_lcd, 20);
#endif

#ifdef CMSIS_V2
  osTimerId_t timer_lcd;
  timer_lcd = osTimerNew(TouchCheckTimerCallback, osTimerPeriodic, NULL, NULL);
  osTimerStart(timer_lcd, 20);
#endif
}

/**
  * @brief  Configure the MPU attributes as Normal Non Cacheable for SRAM1/2.
  * @note   The Base Address is 0x20010000 since this memory interface is the AXI.
  *         The Region Size is 256KB, it is related to SRAM1 and SRAM2  memory size.
  * @param  None
  * @retval None
  */
static void MPU_Config(void)
{
  MPU_Region_InitTypeDef MPU_InitStruct;

  /* Disable the MPU */
  HAL_MPU_Disable();

  /* Configure the MPU as Normal Non Cacheable for the SRAM1 and SRAM2 */
  MPU_InitStruct.Enable = MPU_REGION_ENABLE;
  MPU_InitStruct.BaseAddress = 0x20010000;
  MPU_InitStruct.Size = MPU_REGION_SIZE_256KB;
  MPU_InitStruct.AccessPermission = MPU_REGION_FULL_ACCESS;
  MPU_InitStruct.IsBufferable = MPU_ACCESS_NOT_BUFFERABLE;
  MPU_InitStruct.IsCacheable = MPU_ACCESS_NOT_CACHEABLE;
  MPU_InitStruct.IsShareable = MPU_ACCESS_SHAREABLE;
  MPU_InitStruct.Number = MPU_REGION_NUMBER1;
  MPU_InitStruct.TypeExtField = MPU_TEX_LEVEL1;
  MPU_InitStruct.SubRegionDisable = 0x00;
  MPU_InitStruct.DisableExec = MPU_INSTRUCTION_ACCESS_ENABLE;

  HAL_MPU_ConfigRegion(&MPU_InitStruct);

  /* Enable the MPU */
  HAL_MPU_Enable(MPU_PRIVILEGED_DEFAULT);
}

/* USER CODE END 4 */

void StartDefaultTask(void const * argument)
{

  /* init code for USB_DEVICE */
  MX_USB_DEVICE_Init();

  /* init code for FATFS */
  MX_FATFS_Init();

/* Graphic application */
  GRAPHICS_MainTask();

  /* USER CODE BEGIN 5 */
  /* Infinite loop */
  for(;;)
  {
    osDelay(1000);
  }
  /* USER CODE END 5 */
}

void HAL_TIM_PeriodElapsedCallback(TIM_HandleTypeDef *htim)
{
  if (htim->Instance == TIM1) {
    HAL_IncTick();
  }
  /* USER CODE BEGIN Callback 1 */
  static uint16_t count = 3;
  if(htim->Instance == TIM12){
    updateSysTimeBySecond();
    if(System_Restart_Request == 1)
    {
      count--;
      if(count == 0)
        NVIC_SystemReset();
    }
    else if(System_Restart_Request == 2)
    {
      count = 3;
      System_Restart_Request = 0;
    }
  }
  /* USER CODE END Callback 1 */
}

void Error_Handler(void)
{
}

/************************ (C) COPYRIGHT STMicroelectronics *****END OF FILE****/

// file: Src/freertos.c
/* USER CODE BEGIN Header */
/**
  ******************************************************************************
  * File Name          : freertos.c
  * Description        : Code for freertos applications
  ******************************************************************************
  * @attention
  *
  * <h2><center>&copy; Copyright (c) 2021 STMicroelectronics.
  * All rights reserved.</center></h2>
  *
  * This software component is licensed by ST under Ultimate Liberty license
  * SLA0044, the "License"; You may not use this file except in compliance with
  * the License. You may obtain a copy of the License at:
  *                             www.st.com/SLA0044
  *
  ******************************************************************************
  */
/* USER CODE END Header */

#include "FreeRTOS.h"
#include "task.h"
#include "main.h"

/* Hook prototypes */
void vApplicationIdleHook(void);
void vApplicationTickHook(void);

/* USER CODE BEGIN 2 */
__weak void vApplicationIdleHook( void )
{
   /* vApplicationIdleHook() will only be called if configUSE_IDLE_HOOK is set
   to 1 in FreeRTOSConfig.h. It will be called on each iteration of the idle
   task. It is essential that code added to this hook function never attempts
   to block in any way (for example, call xQueueReceive() with a block time
   specified, or call vTaskDelay()). If the application makes use of the
   vTaskDelete() API function (as this demo application does) then it is also
   important that vApplicationIdleHook() is permitted to return to its calling
   function, because it is the responsibility of the idle task to clean up
   memory allocated by the kernel to any task that has since been deleted. */
}
/* USER CODE END 2 */

/* USER CODE BEGIN 3 */
__weak void vApplicationTickHook( void )
{
   /* This function will be called by each tick interrupt if
   configUSE_TICK_HOOK is set to 1 in FreeRTOSConfig.h. User code can be
   added here, but the tick hook is called from an interrupt context, so
   code must not attempt to block, and only the interrupt safe FreeRTOS API
   functions can be used (those that end in FromISR()). */
}
/* USER CODE END 3 */

/************************ (C) COPYRIGHT STMicroelectronics *****END OF FILE****/
